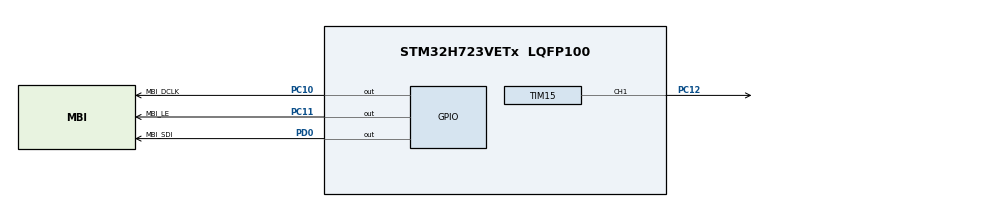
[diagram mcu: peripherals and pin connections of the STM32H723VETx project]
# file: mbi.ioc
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CORTEX_M7.default_mode_Activation=1
Mcu.Family=STM32H7
Mcu.Name=STM32H723VETx
Mcu.Package=LQFP100
NVIC.PriorityGroup=NVIC_PRIORITYGROUP_4
PC10.GPIO_Label=MBI_DCLK
PC10.GPIO_Speed=GPIO_SPEED_FREQ_VERY_HIGH
PC10.Signal=GPIO_Output
PC11.GPIO_Label=MBI_LE
PC11.GPIO_Speed=GPIO_SPEED_FREQ_VERY_HIGH
PC11.Signal=GPIO_Output
PC12.GPIO_Speed=GPIO_SPEED_FREQ_VERY_HIGH
PC12.Signal=S_TIM15_CH1
PD0.GPIO_Label=MBI_SDI
PD0.GPIO_Speed=GPIO_SPEED_FREQ_VERY_HIGH
PD0.Signal=GPIO_Output
PH0-OSC_IN.Mode=HSE-External-Oscillator
PH0-OSC_IN.Signal=RCC_OSC_IN
PH1-OSC_OUT.Mode=HSE-External-Oscillator
PH1-OSC_OUT.Signal=RCC_OSC_OUT
ProjectManager.HeapSize=0x200
ProjectManager.StackSize=0x400
ProjectManager.TargetToolchain=STM32CubeIDE
RCC.ADCFreq_Value=52406250
RCC.APB1Freq_Value=136500000
RCC.APB2Freq_Value=136500000
RCC.APB3Freq_Value=136500000
RCC.APB4Freq_Value=136500000
RCC.CortexFreq_Value=273000000
RCC.D1PPRE=RCC_APB3_DIV2
RCC.D2PPRE1=RCC_APB1_DIV2
RCC.D2PPRE2=RCC_APB2_DIV2
RCC.D3PPRE=RCC_APB4_DIV2
RCC.DIVM1=2
RCC.DIVN1=21
RCC.DIVP1=1
RCC.HCLKFreq_Value=273000000
RCC.HSE_VALUE=26000000
RCC.PLL2FRACN=0
RCC.PLL3FRACN=0
RCC.PLLFRACN=0
RCC.PLLSourceVirtual=RCC_PLLSOURCE_HSE
RCC.SYSCLKFreq_VALUE=273000000
RCC.SYSCLKSource=RCC_SYSCLKSOURCE_PLLCLK
RCC.USBFreq_Value=136500000
SH.S_TIM15_CH1.0=TIM15_CH1,PWM Generation1 CH1
TIM15.Channel-PWM\ Generation1\ CH1=TIM_CHANNEL_1
TIM15.Period=44
TIM15.Pulse-PWM\ Generation1\ CH1=22
VP_MEMORYMAP_VS_MEMORYMAP.Mode=CurAppReg
VP_TIM15_VS_ClockSourceITR.Mode=TriggerSource_ITR0
VP_TIM15_VS_ControllerModeReset.Mode=Reset Mode
board=custom

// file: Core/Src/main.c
/* USER CODE BEGIN Header */
/**
  ******************************************************************************
  * @file           : main.c
  * @brief          : Main program body
  ******************************************************************************
  * @attention
  *
  * Copyright (c) 2026 STMicroelectronics.
  * All rights reserved.
  *
  * This software is licensed under terms that can be found in the LICENSE file
  * in the root directory of this software component.
  * If no LICENSE file comes with this software, it is provided AS-IS.
  *
  ******************************************************************************
  */
/* USER CODE END Header */
#include "main.h"
#include "tim.h"
#include "gpio.h"

/* USER CODE BEGIN Includes */
#include "mbi_prog.h"
/* USER CODE END Includes */

/* USER CODE BEGIN PTD */
float power_run_time = 2.0f;   // required by scale()
/* USER CODE END PTD */

void SystemClock_Config(void);
static void MPU_Config(void);

int main(void)
{

  /* MPU Configuration--------------------------------------------------------*/
  MPU_Config();

  /* MCU Configuration--------------------------------------------------------*/

  /* Reset of all peripherals, Initializes the Flash interface and the Systick. */
  HAL_Init();

  /* Configure the system clock */
  SystemClock_Config();

  /* Initialize all configured peripherals */
  MX_GPIO_Init();
  MX_TIM15_Init();
  /* USER CODE BEGIN 2 */

  mbi_init();

  PixelColor_t test =
  {
//      .R1 = 0xFFFF,
//      .R2 = 0xFFFF,
//      .G1 = 0xFFFF,
      .B1 = 0xFFFF,
//      .A1 = 0xFFFF,
//      .A2 = 0xFFFF,
//      .L1 = 0xFFFF,
//      .L2 = 0xFFFF
  };

  mbi_set_led(23,test);
  mbi_update();

  /* USER CODE END 2 */

  /* Infinite loop */
  while (1)
  {

    /* USER CODE BEGIN 3 */
//	  for(uint8_t i=1;i<=24;i++)
//	  {
//	      mbi_reset_leds();
//
//	      PixelColor_t p=
//	      {
//	          .R1=65280,
//	          .R2=65280,
//	          .G1=65280,
//	          .B1=0,
//	          .A1=0,
//	          .A2=0,
//	          .L1=0,
//	          .L2=0
//	      };
//
//	      mbi_set_led(i,p);
//	      mbi_update();
//
//	      HAL_Delay(200);
//	  }
  }
  /* USER CODE END 3 */
}

void SystemClock_Config(void)
{
  RCC_OscInitTypeDef RCC_OscInitStruct = {0};
  RCC_ClkInitTypeDef RCC_ClkInitStruct = {0};

  /** Supply configuration update enable
  */
  HAL_PWREx_ConfigSupply(PWR_LDO_SUPPLY);

  /** Configure the main internal regulator output voltage
  */
  __HAL_PWR_VOLTAGESCALING_CONFIG(PWR_REGULATOR_VOLTAGE_SCALE0);

  while(!__HAL_PWR_GET_FLAG(PWR_FLAG_VOSRDY)) {}

  /** Initializes the RCC Oscillators according to the specified parameters
  * in the RCC_OscInitTypeDef structure.
  */
  RCC_OscInitStruct.OscillatorType = RCC_OSCILLATORTYPE_HSE;
  RCC_OscInitStruct.HSEState = RCC_HSE_ON;
  RCC_OscInitStruct.PLL.PLLState = RCC_PLL_ON;
  RCC_OscInitStruct.PLL.PLLSource = RCC_PLLSOURCE_HSE;
  RCC_OscInitStruct.PLL.PLLM = 2;
  RCC_OscInitStruct.PLL.PLLN = 21;
  RCC_OscInitStruct.PLL.PLLP = 1;
  RCC_OscInitStruct.PLL.PLLQ = 2;
  RCC_OscInitStruct.PLL.PLLR = 2;
  RCC_OscInitStruct.PLL.PLLRGE = RCC_PLL1VCIRANGE_3;
  RCC_OscInitStruct.PLL.PLLVCOSEL = RCC_PLL1VCOWIDE;
  RCC_OscInitStruct.PLL.PLLFRACN = 0;
  if (HAL_RCC_OscConfig(&RCC_OscInitStruct) != HAL_OK)
  {
    Error_Handler();
  }

  /** Initializes the CPU, AHB and APB buses clocks
  */
  RCC_ClkInitStruct.ClockType = RCC_CLOCKTYPE_HCLK|RCC_CLOCKTYPE_SYSCLK
                              |RCC_CLOCKTYPE_PCLK1|RCC_CLOCKTYPE_PCLK2
                              |RCC_CLOCKTYPE_D3PCLK1|RCC_CLOCKTYPE_D1PCLK1;
  RCC_ClkInitStruct.SYSCLKSource = RCC_SYSCLKSOURCE_PLLCLK;
  RCC_ClkInitStruct.SYSCLKDivider = RCC_SYSCLK_DIV1;
  RCC_ClkInitStruct.AHBCLKDivider = RCC_HCLK_DIV1;
  RCC_ClkInitStruct.APB3CLKDivider = RCC_APB3_DIV2;
  RCC_ClkInitStruct.APB1CLKDivider = RCC_APB1_DIV2;
  RCC_ClkInitStruct.APB2CLKDivider = RCC_APB2_DIV2;
  RCC_ClkInitStruct.APB4CLKDivider = RCC_APB4_DIV2;

  if (HAL_RCC_ClockConfig(&RCC_ClkInitStruct, FLASH_LATENCY_3) != HAL_OK)
  {
    Error_Handler();
  }
}

 /* MPU Configuration */

void MPU_Config(void)
{
  MPU_Region_InitTypeDef MPU_InitStruct = {0};

  /* Disables the MPU */
  HAL_MPU_Disable();

  /** Initializes and configures the Region and the memory to be protected
  */
  MPU_InitStruct.Enable = MPU_REGION_ENABLE;
  MPU_InitStruct.Number = MPU_REGION_NUMBER0;
  MPU_InitStruct.BaseAddress = 0x0;
  MPU_InitStruct.Size = MPU_REGION_SIZE_4GB;
  MPU_InitStruct.SubRegionDisable = 0x87;
  MPU_InitStruct.TypeExtField = MPU_TEX_LEVEL0;
  MPU_InitStruct.AccessPermission = MPU_REGION_NO_ACCESS;
  MPU_InitStruct.DisableExec = MPU_INSTRUCTION_ACCESS_DISABLE;
  MPU_InitStruct.IsShareable = MPU_ACCESS_SHAREABLE;
  MPU_InitStruct.IsCacheable = MPU_ACCESS_NOT_CACHEABLE;
  MPU_InitStruct.IsBufferable = MPU_ACCESS_NOT_BUFFERABLE;

  HAL_MPU_ConfigRegion(&MPU_InitStruct);
  /* Enables the MPU */
  HAL_MPU_Enable(MPU_PRIVILEGED_DEFAULT);

}

void Error_Handler(void)
{
  __disable_irq();
  while (1)
  {
  }
}
